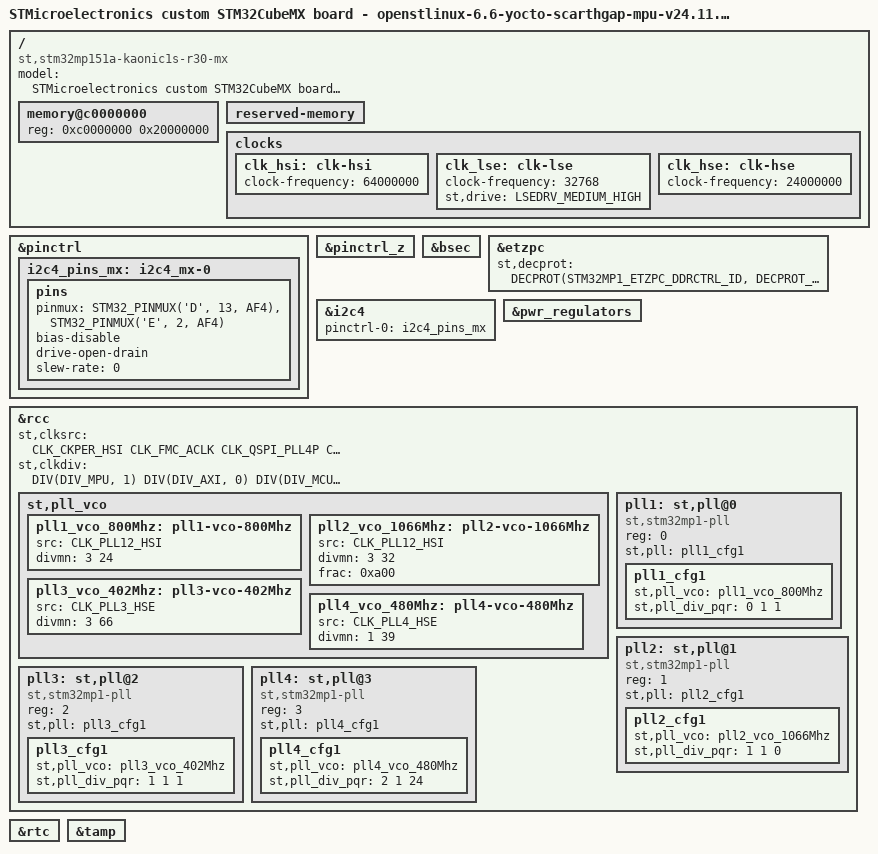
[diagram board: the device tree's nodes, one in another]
// SPDX-License-Identifier: (GPL-2.0-or-later OR BSD-3-Clause)
/*
 * Copyright (C) 2026, STMicroelectronics - All Rights Reserved
 * Author: STM32CubeMX code generation for STMicroelectronics.
 */

/* For more information on Device Tree configuration, please refer to
 * https://wiki.st.com/stm32mpu/wiki/Category:Device_tree_configuration
 */

/dts-v1/;

#include <dt-bindings/pinctrl/stm32-pinfunc.h>
#include <dt-bindings/clock/stm32mp1-clksrc.h>
#include <dt-bindings/soc/stm32mp15-etzpc.h>
#include "stm32mp151.dtsi"
#include "stm32mp15xa.dtsi"
#include "stm32mp15xxab-pinctrl.dtsi"

/* USER CODE BEGIN includes */
/* USER CODE END includes */

/ {
	model = "STMicroelectronics custom STM32CubeMX board - openstlinux-6.6-yocto-scarthgap-mpu-v24.11.06";
	compatible = "st,stm32mp151a-kaonic1s-r30-mx", "st,stm32mp151";

	memory@c0000000 {
		device_type = "memory";
		reg = <0xc0000000 0x20000000>;

		/* USER CODE BEGIN memory */
		/* USER CODE END memory */
	};

	reserved-memory {
		#address-cells = <1>;
		#size-cells = <1>;
		ranges;

		/* USER CODE BEGIN reserved-memory */
		/* USER CODE END reserved-memory */
	};

	/* USER CODE BEGIN root */
	/* USER CODE END root */

	clocks {
		/* USER CODE BEGIN clocks */
		/* USER CODE END clocks */

		clk_hsi: clk-hsi {
			clock-frequency = <64000000>;

			/* USER CODE BEGIN clk_hsi */
			/* USER CODE END clk_hsi */
		};
		clk_lse: clk-lse {
			clock-frequency = <32768>;
			st,drive = < LSEDRV_MEDIUM_HIGH >;

			/* USER CODE BEGIN clk_lse */
			/* USER CODE END clk_lse */
		};
		clk_hse: clk-hse {
			clock-frequency = <24000000>;

			/* USER CODE BEGIN clk_hse */
			/* USER CODE END clk_hse */
		};
	};

}; /*root*/

/*Warning: the configuration of the secured GPIOs should be added in (addons) User Section*/
&pinctrl {
	i2c4_pins_mx: i2c4_mx-0 {
		pins {
			pinmux = <STM32_PINMUX('D', 13, AF4)>, /* I2C4_SDA */
					 <STM32_PINMUX('E', 2, AF4)>; /* I2C4_SCL */
			bias-disable;
			drive-open-drain;
			slew-rate = <0>;
		};
	};

	/* USER CODE BEGIN pinctrl */
	/* USER CODE END pinctrl */
};

&pinctrl_z {
	/* USER CODE BEGIN pinctrl_z */
	/* USER CODE END pinctrl_z */
};

&bsec {
	status = "okay";

	/* USER CODE BEGIN bsec */
	/* USER CODE END bsec */
};

&etzpc {
	status = "okay";
	st,decprot = <
	/*"NS_R S_W" peripherals*/
	DECPROT(STM32MP1_ETZPC_DDRCTRL_ID, DECPROT_NS_R_S_W, DECPROT_LOCK)
	DECPROT(STM32MP1_ETZPC_DDRPHYC_ID, DECPROT_NS_R_S_W, DECPROT_LOCK)
	/*"Non Secured" peripherals*/
	DECPROT(STM32MP1_ETZPC_DMA1_ID, DECPROT_NS_RW, DECPROT_UNLOCK)
	DECPROT(STM32MP1_ETZPC_DMA2_ID, DECPROT_NS_RW, DECPROT_UNLOCK)
	DECPROT(STM32MP1_ETZPC_DMAMUX_ID, DECPROT_NS_RW, DECPROT_UNLOCK)
	DECPROT(STM32MP1_ETZPC_FMC_ID, DECPROT_NS_RW, DECPROT_UNLOCK)
	DECPROT(STM32MP1_ETZPC_I2C1_ID, DECPROT_NS_RW, DECPROT_UNLOCK)
	DECPROT(STM32MP1_ETZPC_I2C2_ID, DECPROT_NS_RW, DECPROT_UNLOCK)
	DECPROT(STM32MP1_ETZPC_I2C4_ID, DECPROT_NS_RW, DECPROT_UNLOCK)
	DECPROT(STM32MP1_ETZPC_SPI1_ID, DECPROT_NS_RW, DECPROT_UNLOCK)
	DECPROT(STM32MP1_ETZPC_SPI2_ID, DECPROT_NS_RW, DECPROT_UNLOCK)
	DECPROT(STM32MP1_ETZPC_QSPI_ID, DECPROT_NS_RW, DECPROT_UNLOCK)
	DECPROT(STM32MP1_ETZPC_DLYBQ_ID, DECPROT_NS_RW, DECPROT_UNLOCK)
	DECPROT(STM32MP1_ETZPC_SPI3_ID, DECPROT_NS_RW, DECPROT_UNLOCK)
	DECPROT(STM32MP1_ETZPC_SPI4_ID, DECPROT_NS_RW, DECPROT_UNLOCK)
	DECPROT(STM32MP1_ETZPC_SPI6_ID, DECPROT_NS_RW, DECPROT_UNLOCK)
	DECPROT(STM32MP1_ETZPC_USART1_ID, DECPROT_NS_RW, DECPROT_UNLOCK)
	DECPROT(STM32MP1_ETZPC_USART2_ID, DECPROT_NS_RW, DECPROT_UNLOCK)
	DECPROT(STM32MP1_ETZPC_USART3_ID, DECPROT_NS_RW, DECPROT_UNLOCK)
	DECPROT(STM32MP1_ETZPC_USART6_ID, DECPROT_NS_RW, DECPROT_UNLOCK)
	DECPROT(STM32MP1_ETZPC_OTG_ID, DECPROT_NS_RW, DECPROT_UNLOCK)
	/*"Secured" peripherals*/
	DECPROT(STM32MP1_ETZPC_STGENC_ID, DECPROT_S_RW, DECPROT_UNLOCK)

	/*Restriction: following IDs are not managed  - please to use User-Section if needed:
		  STM32MP1_ETZPC_SRAMx_ID  STM32MP1_ETZPC_RETRAM_ID  STM32MP1_ETZPC_BKPSRAM_ID*/

	/* USER CODE BEGIN etzpc_decprot */
		/*STM32CubeMX generates a basic and standard configuration for ETZPC.
		Additional device configurations can be added here if needed.
		"etzpc" node could be also overloaded in "addons" User-Section.*/
	/* USER CODE END etzpc_decprot */
	>;

	/* USER CODE BEGIN etzpc */
	/* USER CODE END etzpc */
};

&i2c4 {
	pinctrl-names = "default";
	pinctrl-0 = <&i2c4_pins_mx>;
	status = "okay";

	/* USER CODE BEGIN i2c4 */
	/* USER CODE END i2c4 */
};

&pwr_regulators {
	status = "okay";

	/* USER CODE BEGIN pwr_regulators */
	/* USER CODE END pwr_regulators */
};

&rcc {
	status = "okay";

	/* USER CODE BEGIN rcc */
	/* USER CODE END rcc */

	st,clksrc = <
		CLK_CKPER_HSI
		CLK_FMC_ACLK
		CLK_QSPI_PLL4P
		CLK_SDMMC12_PLL4P
		CLK_STGEN_HSE
		CLK_SPI2S1_PLL4P
		CLK_SPI2S23_CKPER
		CLK_SPI45_PCLK2
		CLK_SPI6_HSI
		CLK_I2C46_HSI
		CLK_USBO_PLL4R
		CLK_I2C12_PCLK1
		CLK_UART1_PCLK5
		CLK_UART24_PCLK1
		CLK_UART35_PCLK1
		CLK_UART6_PCLK2
		CLK_MPU_PLL1P
		CLK_AXI_PLL2P
		CLK_MCU_PLL3P
		CLK_RTC_LSE
		CLK_MCO1_DISABLED
		CLK_MCO2_DISABLED
	>;
	st,clkdiv = <
		DIV(DIV_MPU, 1)
		DIV(DIV_AXI, 0)
		DIV(DIV_MCU, 0)
		DIV(DIV_APB1, 1)
		DIV(DIV_APB2, 1)
		DIV(DIV_APB3, 1)
		DIV(DIV_APB4, 1)
		DIV(DIV_APB5, 2)
		DIV(DIV_RTC, 0)
		DIV(DIV_MCO1, 0)
		DIV(DIV_MCO2, 0)
	>;
	st,pll_vco {
		pll1_vco_800Mhz: pll1-vco-800Mhz {
			src = < CLK_PLL12_HSI >;
			divmn = < 3 24 >;
		};
		pll2_vco_1066Mhz: pll2-vco-1066Mhz {
			src = < CLK_PLL12_HSI >;
			divmn = < 3 32 >;
			frac = < 0xa00 >;
		};
		pll3_vco_402Mhz: pll3-vco-402Mhz {
			src = < CLK_PLL3_HSE >;
			divmn = < 3 66 >;
		};
		pll4_vco_480Mhz: pll4-vco-480Mhz {
			src = < CLK_PLL4_HSE >;
			divmn = < 1 39 >;
		};
		/* USER CODE BEGIN rcc_st-pll_vco */
		/* USER CODE END rcc_st-pll_vco */
	};

	pll1:st,pll@0 {
		compatible = "st,stm32mp1-pll";
		reg = <0>;

		st,pll = < &pll1_cfg1 >;

		pll1_cfg1: pll1_cfg1 {
			st,pll_vco = < &pll1_vco_800Mhz >;
			st,pll_div_pqr = < 0 1 1 >;
		};
		/* USER CODE BEGIN pll1 */
		/* USER CODE END pll1 */
	};

	pll2:st,pll@1 {
		compatible = "st,stm32mp1-pll";
		reg = <1>;

		st,pll = < &pll2_cfg1 >;

		pll2_cfg1: pll2_cfg1 {
			st,pll_vco = < &pll2_vco_1066Mhz >;
			st,pll_div_pqr = < 1 1 0 >;
		};
		/* USER CODE BEGIN pll2 */
		/* USER CODE END pll2 */
	};

	pll3:st,pll@2 {
		compatible = "st,stm32mp1-pll";
		reg = <2>;

		st,pll = < &pll3_cfg1 >;

		pll3_cfg1: pll3_cfg1 {
			st,pll_vco = < &pll3_vco_402Mhz >;
			st,pll_div_pqr = < 1 1 1 >;
		};
		/* USER CODE BEGIN pll3 */
		/* USER CODE END pll3 */
	};

	pll4:st,pll@3 {
		compatible = "st,stm32mp1-pll";
		reg = <3>;

		st,pll = < &pll4_cfg1 >;

		pll4_cfg1: pll4_cfg1 {
			st,pll_vco = < &pll4_vco_480Mhz >;
			st,pll_div_pqr = < 2 1 24 >;
		};
		/* USER CODE BEGIN pll4 */
		/* USER CODE END pll4 */
	};

};

&rtc {
	status = "okay";

	/* USER CODE BEGIN rtc */
	/* USER CODE END rtc */
};

&tamp {
	status = "okay";

	/* USER CODE BEGIN tamp */
	/* USER CODE END tamp */
};

/* USER CODE BEGIN addons */
/* USER CODE END addons */

